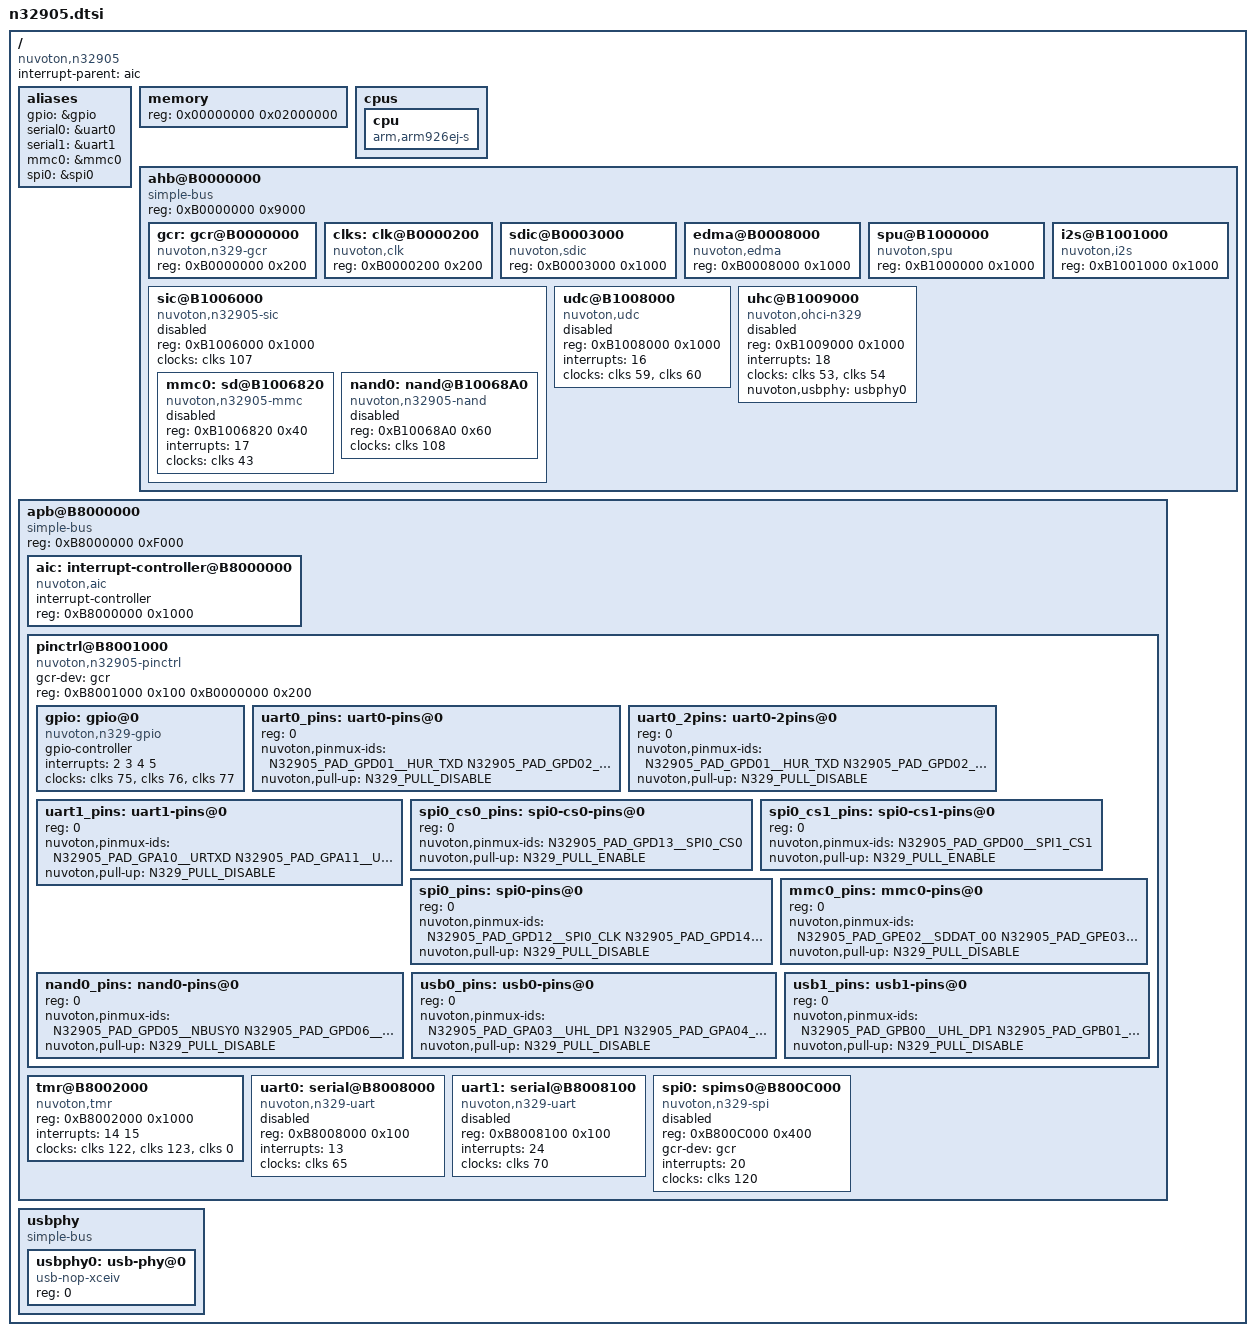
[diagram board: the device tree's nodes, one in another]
/*
 * Copyright (C) 2014 Michael P. Thompson, Inc. All Rights Reserved.
 *
 * This program is free software; you can redistribute it and/or modify
 * it under the terms of the GNU General Public License as published by
 * the Free Software Foundation; either version 2 of the License, or
 * (at your option) any later version.
 *
 * This program is distributed in the hope that it will be useful,
 * but WITHOUT ANY WARRANTY; without even the implied warranty of
 * MERCHANTABILITY or FITNESS FOR A PARTICULAR PURPOSE.  See the
 * GNU General Public License for more details.
 *
 * You should have received a copy of the GNU General Public License along
 * with this program; if not, write to the Free Software Foundation, Inc.,
 * 51 Franklin Street, Fifth Floor, Boston, MA 02110-1301 USA.
 */

#include "skeleton.dtsi"
#include "n32905-pinfunc.h"

/ {
	compatible = "nuvoton,n32905", "nuvoton,n329";

	interrupt-parent = <&aic>;

	aliases {
		gpio = &gpio;
		serial0 = &uart0;
		serial1 = &uart1;
		mmc0 = &mmc0;
		spi0 = &spi0;
	};

	memory {
		reg = <0x00000000 0x02000000>;
	};

	cpus {
		#address-cells = <0>;
		#size-cells = <0>;

		cpu {
			compatible = "arm,arm926ej-s";
			device_type = "cpu";
		};
	};

	ahb@B0000000 {
		compatible = "simple-bus";
		#address-cells = <1>;
		#size-cells = <1>;
		reg = <0xB0000000 0x9000>;
		ranges;

		gcr: gcr@B0000000 {
			compatible = "nuvoton,n329-gcr";
			reg = <0xB0000000 0x200>;
		};

		clks: clk@B0000200 {
			compatible = "nuvoton,clk";
			reg = <0xB0000200 0x200>;
			#clock-cells = <1>;
		};

		sdic@B0003000 {
			compatible = "nuvoton,sdic";
			reg = <0xB0003000 0x1000>;
		};

		edma@B0008000 {
			compatible = "nuvoton,edma";
			reg = <0xB0008000 0x1000>;
		};

		spu@B1000000 {
			compatible = "nuvoton,spu";
			reg = <0xB1000000 0x1000>;
		};

		i2s@B1001000 {
			compatible = "nuvoton,i2s";
			reg = <0xB1001000 0x1000>;
		};

		sic@B1006000 {
			#address-cells = <1>;
			#size-cells = <1>;
			compatible = "nuvoton,n32905-sic";
			reg = <0xB1006000 0x1000>;
			clocks = <&clks 107>;
			status = "disabled";
			ranges;

			mmc0: sd@B1006820 {
				compatible = "nuvoton,n32905-mmc";
				reg = <0xB1006820 0x40>;
				interrupts = <17>;
				clocks = <&clks 43>;
				status = "disabled";
			};

			nand0: nand@B10068A0 {
				#address-cells = <1>;
				#size-cells = <1>;
				compatible = "nuvoton,n32905-nand";
				reg = <0xB10068A0 0x60>;
				clocks = <&clks 108>;
				status = "disabled";
			};
		};

		udc@B1008000 {
			compatible = "nuvoton,udc";
			reg = <0xB1008000 0x1000>;
			interrupts = <16>;
			clocks = <&clks 59>, <&clks 60>;
			status = "disabled";
		};

		uhc@B1009000 {
			compatible = "nuvoton,ohci-n329";
			reg = <0xB1009000 0x1000>;
			interrupts = <18>;
			clocks = <&clks 53>, <&clks 54>;
			nuvoton,usbphy = <&usbphy0>;
			status = "disabled";
		};
	};

	apb@B8000000 {
		compatible = "simple-bus";
		#address-cells = <1>;
		#size-cells = <1>;
		reg = <0xB8000000 0xF000>;
		ranges;

		aic: interrupt-controller@B8000000 {
			compatible = "nuvoton,aic";
			interrupt-controller;
			#interrupt-cells = <1>;
			reg = <0xB8000000 0x1000>;
		};

		pinctrl@B8001000 {
			#address-cells = <1>;
			#size-cells = <0>;
			compatible = "nuvoton,n32905-pinctrl";
			gcr-dev = <&gcr>;
			reg = <0xB8001000 0x100 0xB0000000 0x200>;

			gpio: gpio@0 {
				compatible = "nuvoton,n329-gpio";
				gpio-controller;
				#gpio-cells = <2>;
				interrupts = <2 3 4 5>;
				clocks = <&clks 75>, <&clks 76>, <&clks 77>;
			};

			uart0_pins: uart0-pins@0 {
				reg = <0>;
				nuvoton,pinmux-ids = <
					N32905_PAD_GPD01__HUR_TXD
					N32905_PAD_GPD02__HUR_RXD
					N32905_PAD_GPD03__HUR_CTS
					N32905_PAD_GPD04__HUR_RTS
				>;
				nuvoton,pull-up = <N329_PULL_DISABLE>;
			};

			uart0_2pins: uart0-2pins@0 {
				reg = <0>;
				nuvoton,pinmux-ids = <
					N32905_PAD_GPD01__HUR_TXD
					N32905_PAD_GPD02__HUR_RXD
				>;
				nuvoton,pull-up = <N329_PULL_DISABLE>;
			};

			uart1_pins: uart1-pins@0 {
				reg = <0>;
				nuvoton,pinmux-ids = <
					N32905_PAD_GPA10__URTXD
					N32905_PAD_GPA11__URRXD
				>;
				nuvoton,pull-up = <N329_PULL_DISABLE>;
			};

			spi0_cs0_pins: spi0-cs0-pins@0 {
				reg = <0>;
				nuvoton,pinmux-ids = <
					N32905_PAD_GPD13__SPI0_CS0
				>;
				nuvoton,pull-up = <N329_PULL_ENABLE>;
			};

			spi0_cs1_pins: spi0-cs1-pins@0 {
				reg = <0>;
				nuvoton,pinmux-ids = <
					N32905_PAD_GPD00__SPI1_CS1
				>;
				nuvoton,pull-up = <N329_PULL_ENABLE>;
			};

			spi0_pins: spi0-pins@0 {
				reg = <0>;
				nuvoton,pinmux-ids = <
					N32905_PAD_GPD12__SPI0_CLK
					N32905_PAD_GPD14__SPI0_DI
					N32905_PAD_GPD15__SPI0_DO
				>;
				nuvoton,pull-up = <N329_PULL_DISABLE>;
			};

			mmc0_pins: mmc0-pins@0 {
				reg = <0>;
				nuvoton,pinmux-ids = <
					N32905_PAD_GPE02__SDDAT_00
					N32905_PAD_GPE03__SDDAT_01
					N32905_PAD_GPE04__SDDAT_02
					N32905_PAD_GPE05__SDDAT_03
					N32905_PAD_GPE06__SDCMD
					N32905_PAD_GPE07__SDCLK
					N32905_PAD_GPA01__SD_CD
				>;
				nuvoton,pull-up = <N329_PULL_DISABLE>;
			};

			nand0_pins: nand0-pins@0 {
				reg = <0>;
				nuvoton,pinmux-ids = <
					N32905_PAD_GPD05__NBUSY0
					N32905_PAD_GPD06__NBUSY1
					N32905_PAD_GPD08__NWR
					N32905_PAD_GPD07__NRE
					N32905_PAD_GPE08__NCS0
					N32905_PAD_GPE09__NCS1
					N32905_PAD_GPE10__NALE
					N32905_PAD_GPE11__NCLE
				>;
				nuvoton,pull-up = <N329_PULL_DISABLE>;
			};

			usb0_pins: usb0-pins@0 {
				reg = <0>;
				nuvoton,pinmux-ids = <
					N32905_PAD_GPA03__UHL_DP1
					N32905_PAD_GPA04__UHL_DM1
				>;
				nuvoton,pull-up = <N329_PULL_DISABLE>;
			};

			usb1_pins: usb1-pins@0 {
				reg = <0>;
				nuvoton,pinmux-ids = <
					N32905_PAD_GPB00__UHL_DP1
					N32905_PAD_GPB01__UHL_DM1
				>;
				nuvoton,pull-up = <N329_PULL_DISABLE>;
			};
		};

		tmr@B8002000 {
			compatible = "nuvoton,tmr";
			reg = <0xB8002000 0x1000>;
			interrupts = <14 15>;
			clocks = <&clks 122>, <&clks 123>, <&clks 0>;
		};

		uart0: serial@B8008000 {
			compatible = "nuvoton,n329-uart";
			reg = <0xB8008000 0x100>;
			interrupts = <13>;
			clocks = <&clks 65>;
			status = "disabled";
		};

		uart1: serial@B8008100 {
			compatible = "nuvoton,n329-uart";
			reg = <0xB8008100 0x100>;
			interrupts = <24>;
			clocks = <&clks 70>;
			status = "disabled";
		};

		spi0: spims0@B800C000 {
			#address-cells = <1>;
			#size-cells = <0>;		
			reg = <0xB800C000 0x400>;
			compatible = "nuvoton,n329-spi";
			gcr-dev = <&gcr>;
			interrupts = <20>;
			clocks = <&clks 120>;
			status = "disabled";
		};
	};

	usbphy {
		compatible = "simple-bus";
		#address-cells = <1>;
		#size-cells = <0>;

		usbphy0: usb-phy@0 {
			reg = <0>;
			compatible = "usb-nop-xceiv";
		};
	};
};
